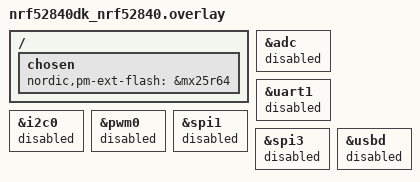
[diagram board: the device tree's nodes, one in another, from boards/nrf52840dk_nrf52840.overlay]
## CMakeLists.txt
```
#
# Copyright (c) 2021 Nordic Semiconductor ASA
#
# SPDX-License-Identifier: LicenseRef-Nordic-5-Clause
#

cmake_minimum_required(VERSION 3.20.0)

find_package(Zephyr REQUIRED HINTS $ENV{ZEPHYR_BASE})
project(matter-lock)

# Enable GNU STD support.
include(${ZEPHYR_CONNECTEDHOMEIP_MODULE_DIR}/config/nrfconnect/app/enable-gnu-std.cmake)

# NORDIC SDK APP START

# Include all source files that are located in the Matter common directory.
include(${ZEPHYR_NRF_MODULE_DIR}/samples/matter/common/cmake/source_common.cmake)

# Include Data Model utils
include(${ZEPHYR_NRF_MODULE_DIR}/samples/matter/common/cmake/data_model.cmake)

include(${ZEPHYR_NRF_MODULE_DIR}/samples/matter/common/cmake/zap_helpers.cmake)
ncs_get_zap_parent_dir(ZAP_PARENT_DIR)

target_include_directories(app PRIVATE
  src
  ${ZAP_PARENT_DIR}
)

SET(access_srcs
  src/access/access_data_types.cpp
  src/access/access_manager_credentials.cpp
  src/access/access_manager_users.cpp
  src/access/access_manager.cpp
  src/access/access_storage.cpp
)

if(CONFIG_LOCK_SCHEDULES)
  LIST(APPEND access_srcs src/access/access_manager_schedules.cpp)
endif()

target_sources(app PRIVATE
  src/app_task.cpp
  src/bolt_lock_manager.cpp
  src/main.cpp
  src/zcl_callbacks.cpp
  ${access_srcs}
)

if(CONFIG_THREAD_WIFI_SWITCHING)
  target_sources(app PRIVATE
    src/thread_wifi_switch.cpp
  )
endif()

# Do not treat warnings as errors while the variable may be uninitialized for this sample data model.
# In the door-lock-server implementation, there is a warning that the C++ "optional"
# variable may be uninitialized, but actually, it is wrongly interpreted by the Zephyr toolchain.
target_compile_options(matter-data-model PRIVATE -Wno-error=maybe-uninitialized)

ncs_configure_data_model()

# NORDIC SDK APP END
```

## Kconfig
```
#
# Copyright (c) 2021 Nordic Semiconductor
#
# SPDX-License-Identifier: LicenseRef-Nordic-5-Clause
#

mainmenu "Matter Lock sample application"

config LOCK_MAX_NUM_USERS
	int "Maximum number of users supported by the lock"
	default 10

config LOCK_MAX_NUM_CREDENTIALS_PER_USER
	int "Maximum total number of credentials per one user supported by the lock"
	default 4

config LOCK_MAX_NUM_CREDENTIALS_PER_TYPE
	int "Maximum number of credentials of given type supported by the lock"
	default 15

config LOCK_MAX_CREDENTIAL_LENGTH
	int "Maximum length of the single credential supported by the lock"
	default 10

config LOCK_PASS_CREDENTIALS_TO_SET_LOCK_STATE
	bool "Pass used credentials when setting the lock state"
	help
	  This option should stay disabled until TC-DRLK-2.3 is fixed.
	  Related issue: https://github.com/project-chip/connectedhomeip/issues/38222

config LOCK_SCHEDULES
	bool "Support for WeekDay, YearDay and Holiday schedules in lock"
	help
	  This option adds support for an optional Timed Schedule Access Lock feature.
	  You can use Week Day, Year Day and Holiday schedules to restrict access for a
	  specific user for a defined time window. For example, use it to
	  give the user access only for three days in week.

if LOCK_SCHEDULES

config LOCK_MAX_WEEKDAY_SCHEDULES_PER_USER
	int "Maximum number of WeekDay schedules per one user supported by the lock"
	default 5

config LOCK_MAX_YEARDAY_SCHEDULES_PER_USER
	int "Maximum number of YearDay schedules per one user supported by the lock"
	default 5

config LOCK_MAX_HOLIDAY_SCHEDULES
	int "Maximum number of Holiday schedules supported by the lock"
	default 5

endif

config LOCK_ENABLE_DEBUG
	bool "Debug features to print users and credentials"
	depends on SHELL
	help
	  Debug features allows to checking and printing current users, their state, and
	  associated credentials. Use these with shell commands combinations to read saved credentials
	  or users, and manage them (add, clear, read).

if LOCK_ENABLE_DEBUG

config LOCK_PRINT_STORAGE_STATUS
	bool "Print storage status after each store call"
	help
	  Debug feature to print the debug-level log that contains information of the entry being stored
	  to persistent storage and how many bytes are left to store the new entry. It can be used to verify
	  whether credential, schedule or user entries are written properly to persistent storage.
	  This option should be disabled in production firmware
	  version.

# This should be deterined based on the maximum possible command length that depends on the LOCK_MAX_CREDENTIAL_LENGTH
config SHELL_CMD_BUFF_SIZE
	default 300

endif

config STATE_LEDS
	bool "Use LEDs to indicate the device state"
	default y
	help
	  Use LEDs to render the current state of the device such as the progress of commissioning of
	  the device into a network or the factory reset initiation. Note that setting this option to
	  'n' does not disable the LED indicating the state of the simulated bolt.

config THREAD_WIFI_SWITCHING
	bool "Switching between Thread and Wi-Fi"
	depends on SOC_SERIES_NRF53X
	depends on NET_L2_OPENTHREAD
	depends on CHIP_WIFI
	depends on !CHIP_FACTORY_RESET_ERASE_SETTINGS
	select EXPERIMENTAL
	help
	  Build the application with both Thread and Wi-Fi support and initialize
	  either transport based on the current configuration. A user can switch
	  between Thread and Wi-Fi by pressing and holding Button 3 for more than
	  10 seconds. During the switching, the device is automatically factory
	  reset and rebooted.

if THREAD_WIFI_SWITCHING

config THREAD_WIFI_SWITCHING_SHELL
	bool "Shell command for switching between Thread and Wi-Fi"
	default y if SHELL
	help
	  Add "switch_transport" shell command that initiates switching between
	  Thread and Wi-Fi transport for Matter protocol stack.

endif # THREAD_WIFI_SWITCHING

# Sample configuration used for Thread networking
if OPENTHREAD

choice OPENTHREAD_NORDIC_LIBRARY_CONFIGURATION
	default OPENTHREAD_NORDIC_LIBRARY_MTD
endchoice

choice OPENTHREAD_DEVICE_TYPE
	default OPENTHREAD_MTD
endchoice

config CHIP_ENABLE_ICD_SUPPORT
	default y

# Reduce Thread TX output power to 0 dBm for SED device
config OPENTHREAD_DEFAULT_TX_POWER
	default 0

endif # OPENTHREAD

if BOARD_NRF7002DK_NRF5340_CPUAPP || SHIELD_NRF7002EK || SHIELD_NRF7002EB2

config CHIP_WIFI
	default y
	select DEPRECATED if SOC_SERIES_NRF53X

config NRF_WIFI_LOW_POWER
	default y

endif # BOARD_NRF7002DK_NRF5340_CPUAPP || SHIELD_NRF7002EK || SHIELD_NRF7002EB2

config NCS_SAMPLE_MATTER_PERSISTENT_STORAGE
	default y

# PSA SSF Crypto Client is not ready for the secure storage backend
if !PSA_SSF_CRYPTO_CLIENT

config NCS_SAMPLE_MATTER_SECURE_STORAGE_BACKEND
	default y if !CHIP_WIFI

config NCS_SAMPLE_MATTER_SETTINGS_STORAGE_BACKEND
	default n if !CHIP_WIFI

endif

# Increase the storage capacity if the schedules are enabled with secure storage
# This also implies increasing of the OT and Matter stacks because some operations
# performed during commissioning seem to allocate stack buffers based on the
# maximum possible secure asset size.
if LOCK_SCHEDULES && NCS_SAMPLE_MATTER_SECURE_STORAGE_BACKEND

config NCS_SAMPLE_MATTER_SECURE_STORAGE_MAX_ENTRY_NUMBER
	default 128

config TRUSTED_STORAGE_BACKEND_AEAD_MAX_DATA_SIZE
	default 3072

config OPENTHREAD_THREAD_STACK_SIZE
	default 7168

config CHIP_TASK_STACK_SIZE
	default 10240

config MAIN_STACK_SIZE
	default 7168

endif

source "$(ZEPHYR_CONNECTEDHOMEIP_MODULE_DIR)/config/nrfconnect/chip-module/Kconfig.features"
source "$(ZEPHYR_CONNECTEDHOMEIP_MODULE_DIR)/config/nrfconnect/chip-module/Kconfig.defaults"
source "$(ZEPHYR_NRF_MODULE_DIR)/samples/matter/common/src/Kconfig"
source "Kconfig.zephyr"
```

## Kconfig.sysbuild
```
#
# Copyright (c) 2023 Nordic Semiconductor ASA
#
# SPDX-License-Identifier: LicenseRef-Nordic-5-Clause
#

# This config has to be enabled manually for variants with shields, because sysbuild does not support it.
config WIFI_NRF70
	default y if BOARD_NRF7002DK

#### Radio core selection
config NRF_DEFAULT_IPC_RADIO
	default y

# Enable IEEE802.15.4 serialization to network core
# This config automatically pulls in the `overlay-802154.conf` in the ipc_radio image
config NETCORE_IPC_RADIO_IEEE802154
	default y if SOC_SERIES_NRF53X && !WIFI_NRF70

# Enable Bluetooth serialization to network core
# This config automatically pulls in the `overlay-bt_hci_ipc.conf` in the ipc_radio image
config NETCORE_IPC_RADIO_BT_HCI_IPC
	default y if SOC_SERIES_NRF53X

#### Bootloader
choice BOOTLOADER
	default BOOTLOADER_MCUBOOT if !BOARD_NRF21540DK
endchoice

if BOOTLOADER_MCUBOOT

#### DFU multi-image support
config DFU_MULTI_IMAGE_PACKAGE_BUILD
	default y

config DFU_MULTI_IMAGE_PACKAGE_APP
	default y

config PM_EXTERNAL_FLASH_MCUBOOT_SECONDARY
	default y

#### DFU network core configuration
if SOC_SERIES_NRF53X

choice MCUBOOT_MODE
	default MCUBOOT_MODE_OVERWRITE_ONLY
endchoice

choice BOOT_SIGNATURE_TYPE
	default BOOT_SIGNATURE_TYPE_RSA
endchoice

config SECURE_BOOT_NETCORE
	default y

config NETCORE_APP_UPDATE
	default y

config DFU_MULTI_IMAGE_PACKAGE_NET
	default y

endif # SOC_SERIES_NRF53X

if BOARD_NRF54L15DK || BOARD_NRF54LM20DK || BOARD_XIAO_NRF54LM20A

# Disable checking the external drivers for nRF54L15 and nRF54LM20 DKs.
config PM_OVERRIDE_EXTERNAL_DRIVER_CHECK
	default y

endif # BOARD_NRF54L15DK || BOARD_NRF54LM20DK || BOARD_XIAO_NRF54LM20A

endif # BOOTLOADER_MCUBOOT

# Store the Wi-Fi firmware patch on external flash by default for nRF5340 with nRF7002
if WIFI_NRF70 && SOC_NRF5340_CPUAPP

choice WIFI_PATCHES_EXT_FLASH_SUPPORT
	default WIFI_PATCHES_EXT_FLASH_STORE

endchoice

config DFU_MULTI_IMAGE_PACKAGE_WIFI_FW_PATCH
	default y

endif # WIFI_NRF70

#### Enable generating factory data
config MATTER_FACTORY_DATA_GENERATE
	default y if !BOARD_NRF21540DK && !BOARD_XIAO_NRF54LM20A

source "share/sysbuild/Kconfig"
```

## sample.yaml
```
sample:
  description: Matter Lock example
  name: Matter Lock
common:
  tags:
    - sysbuild
    - ci_samples_matter
tests:
  sample.matter.lock.debug:
    sysbuild: true
    build_only: true
    integration_platforms:
      - nrf52840dk/nrf52840
      - nrf5340dk/nrf5340/cpuapp
      - nrf7002dk/nrf5340/cpuapp
      - nrf7002dk/nrf5340/cpuapp/nrf7001
      - nrf54l15dk/nrf54l15/cpuapp
      - nrf54l15dk/nrf54l15/cpuapp/ns
      - nrf54lm20dk/nrf54lm20a/cpuapp
    platform_allow:
      - nrf52840dk/nrf52840
      - nrf5340dk/nrf5340/cpuapp
      - nrf7002dk/nrf5340/cpuapp
      - nrf7002dk/nrf5340/cpuapp/nrf7001
      - nrf54l15dk/nrf54l15/cpuapp
      - nrf54l15dk/nrf54l15/cpuapp/ns
      - nrf54lm20dk/nrf54lm20a/cpuapp
  sample.matter.lock.nrf7002eb2.debug:
    sysbuild: true
    build_only: true
    extra_args:
      - lock_SHIELD=nrf7002eb2
      - SB_CONFIG_WIFI_NRF70=y
    integration_platforms:
      - nrf54lm20dk/nrf54lm20a/cpuapp
    platform_allow:
      - nrf54lm20dk/nrf54lm20a/cpuapp
  sample.matter.lock.release:
    sysbuild: true
    build_only: true
    extra_args:
      - FILE_SUFFIX=release
    integration_platforms:
      - nrf52840dk/nrf52840
      - nrf5340dk/nrf5340/cpuapp
      - nrf7002dk/nrf5340/cpuapp
      - nrf7002dk/nrf5340/cpuapp/nrf7001
      - nrf54l15dk/nrf54l15/cpuapp
      - nrf54lm20dk/nrf54lm20a/cpuapp
    platform_allow:
      - nrf52840dk/nrf52840
      - nrf5340dk/nrf5340/cpuapp
      - nrf7002dk/nrf5340/cpuapp
      - nrf7002dk/nrf5340/cpuapp/nrf7001
      - nrf54l15dk/nrf54l15/cpuapp
      - nrf54lm20dk/nrf54lm20a/cpuapp
  sample.matter.lock.nrf7002eb2.release:
    sysbuild: true
    build_only: true
    extra_args:
      - FILE_SUFFIX=release
      - SB_CONFIG_BOOTLOADER_MCUBOOT=y
      - SB_CONFIG_PARTITION_MANAGER=y
      - lock_SHIELD=nrf7002eb2
      - SB_CONFIG_WIFI_NRF70=y
    integration_platforms:
      - nrf54lm20dk/nrf54lm20a/cpuapp
    platform_allow:
      - nrf54lm20dk/nrf54lm20a/cpuapp
  sample.matter.lock.smp_dfu:
    sysbuild: true
    build_only: true
    extra_args:
      - CONFIG_CHIP_DFU_OVER_BT_SMP=y
    integration_platforms:
      - nrf52840dk/nrf52840
      - nrf5340dk/nrf5340/cpuapp
      - nrf7002dk/nrf5340/cpuapp
      - nrf7002dk/nrf5340/cpuapp/nrf7001
      - nrf54l15dk/nrf54l15/cpuapp
      - nrf54lm20dk/nrf54lm20a/cpuapp
    platform_allow:
      - nrf52840dk/nrf52840
      - nrf5340dk/nrf5340/cpuapp
      - nrf7002dk/nrf5340/cpuapp
      - nrf7002dk/nrf5340/cpuapp/nrf7001
      - nrf54l15dk/nrf54l15/cpuapp
      - nrf54lm20dk/nrf54lm20a/cpuapp
  sample.matter.lock.nrf7002eb2.smp_dfu:
    sysbuild: true
    build_only: true
    extra_args:
      - CONFIG_CHIP_DFU_OVER_BT_SMP=y
      - lock_SHIELD=nrf7002eb2
      - SB_CONFIG_WIFI_NRF70=y
    integration_platforms:
      - nrf54lm20dk/nrf54lm20a/cpuapp
    platform_allow:
      - nrf54lm20dk/nrf54lm20a/cpuapp
  sample.matter.lock.no_dfu.no_fd:
    sysbuild: true
    build_only: true
    extra_args:
      - SB_CONFIG_MATTER_OTA=n
    integration_platforms:
      - nrf21540dk/nrf52840
    platform_allow: nrf21540dk/nrf52840
  sample.matter.lock.thread_wifi_switched.smp_dfu:
    sysbuild: true
    build_only: true
    extra_args:
      - lock_SHIELD=nrf7002ek
      - FILE_SUFFIX=thread_wifi_switched
      - SB_CONFIG_WIFI_PATCHES_EXT_FLASH_STORE=y
      - SB_CONFIG_MCUBOOT_UPDATEABLE_IMAGES=3
      - CONFIG_CHIP_DFU_OVER_BT_SMP=y
      - SB_CONFIG_WIFI_NRF70=y
      - SB_CONFIG_DFU_MULTI_IMAGE_PACKAGE_WIFI_FW_PATCH=y
    integration_platforms:
      - nrf5340dk/nrf5340/cpuapp
    platform_allow: nrf5340dk/nrf5340/cpuapp
  sample.matter.lock.nus:
    sysbuild: true
    build_only: true
    extra_args:
      - CONFIG_CHIP_NUS=y
      - CONFIG_BT_APP_PASSKEY=y
      - CONFIG_CHIP_NUS_FIXED_PASSKEY=112233
    integration_platforms:
      - nrf52840dk/nrf52840
      - nrf5340dk/nrf5340/cpuapp
    platform_allow:
      - nrf52840dk/nrf52840
      - nrf5340dk/nrf5340/cpuapp
      - nrf54l15dk/nrf54l15/cpuapp
  sample.matter.lock.schedules:
    sysbuild: true
    build_only: true
    extra_args:
      - lock_SNIPPET=schedules
    integration_platforms:
      - nrf5340dk/nrf5340/cpuapp
    platform_allow:
      - nrf5340dk/nrf5340/cpuapp
  sample.matter.lock.release.power_consumption:
    sysbuild: true
    build_only: true
    extra_args:
      - FILE_SUFFIX=release
      - CONFIG_NCS_SAMPLE_MATTER_LEDS=n
      - CONFIG_NCS_SAMPLE_MATTER_WATCHDOG=n
      - CONFIG_CHIP_ENABLE_PAIRING_AUTOSTART=y
    integration_platforms:
      - nrf52840dk/nrf52840
      - nrf5340dk/nrf5340/cpuapp
      - nrf54l15dk/nrf54l15/cpuapp
      - nrf54lm20dk/nrf54lm20a/cpuapp
    platform_allow:
      - nrf52840dk/nrf52840
      - nrf5340dk/nrf5340/cpuapp
      - nrf54l15dk/nrf54l15/cpuapp
      - nrf54lm20dk/nrf54lm20a/cpuapp
```

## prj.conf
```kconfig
#
# Copyright (c) 2022 Nordic Semiconductor ASA
#
# SPDX-License-Identifier: LicenseRef-Nordic-5-Clause
#

# This sample uses Kconfig.defaults to set options common for all
# samples. This file should contain only options specific for this sample
# or overrides of default values.

# Enable CHIP
CONFIG_CHIP=y
CONFIG_CHIP_PROJECT_CONFIG="src/chip_project_config.h"
CONFIG_CHIP_DEVICE_PRODUCT_NAME="Matter Door Lock"

# Configure ZAP file name
CONFIG_NCS_SAMPLE_MATTER_ZAP_FILE_PATH="${APPLICATION_CONFIG_DIR}/src/default_zap/lock.zap"

# 32774 == 0x8006 (example lock-app)
CONFIG_CHIP_DEVICE_PRODUCT_ID=32774
CONFIG_STD_CPP17=y

# Enable Matter extended announcement and increase duration to 1 hour.
CONFIG_CHIP_BLE_EXT_ADVERTISING=y
CONFIG_CHIP_BLE_ADVERTISING_DURATION=60

# Add support for LEDs and buttons on Nordic development kits
CONFIG_DK_LIBRARY=y

# Bluetooth Low Energy configuration
CONFIG_BT_DEVICE_NAME="MatterLock"

# Suspend devices when the CPU goes into sleep
CONFIG_PM_DEVICE=y

# Other settings
CONFIG_THREAD_NAME=y
CONFIG_MPU_STACK_GUARD=y
CONFIG_RESET_ON_FATAL_ERROR=n
CONFIG_CHIP_LIB_SHELL=y
CONFIG_NCS_SAMPLE_MATTER_TEST_SHELL=y

# Reduce application size
CONFIG_USE_SEGGER_RTT=n
CONFIG_MATTER_LOG_LEVEL_INF=y
CONFIG_CHIP_APP_LOG_LEVEL=3

# Enable Factory Data feature
CONFIG_CHIP_FACTORY_DATA=y
CONFIG_CHIP_FACTORY_DATA_BUILD=y
```

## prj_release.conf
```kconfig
#
# Copyright (c) 2022 Nordic Semiconductor ASA
#
# SPDX-License-Identifier: LicenseRef-Nordic-5-Clause
#

# This sample uses Kconfig.defaults to set options common for all
# samples. This file should contain only options specific for this sample
# or overrides of default values.

# Enable CHIP
CONFIG_CHIP=y
CONFIG_CHIP_PROJECT_CONFIG="src/chip_project_config.h"
CONFIG_CHIP_DEVICE_PRODUCT_NAME="Matter Door Lock"

# Configure ZAP file name
CONFIG_NCS_SAMPLE_MATTER_ZAP_FILE_PATH="${APPLICATION_CONFIG_DIR}/src/default_zap/lock.zap"

# 32774 == 0x8006 (example lock-app)
CONFIG_CHIP_DEVICE_PRODUCT_ID=32774
CONFIG_STD_CPP17=y

# Enable Matter extended announcement and increase duration to 1 hour.
CONFIG_CHIP_BLE_EXT_ADVERTISING=y
CONFIG_CHIP_BLE_ADVERTISING_DURATION=60

# Add support for LEDs and buttons on Nordic development kits
CONFIG_DK_LIBRARY=y

# Bluetooth Low Energy configuration
CONFIG_BT_DEVICE_NAME="MatterLock"

# Suspend devices when the CPU goes into sleep
CONFIG_PM_DEVICE=y

# Enable system reset on fatal error
CONFIG_RESET_ON_FATAL_ERROR=y

# Try to disable unused RAM blocks to reduce power consumption
CONFIG_RAM_POWER_DOWN_LIBRARY=y

# Disable all debug features
CONFIG_USE_SEGGER_RTT=n
CONFIG_SHELL=n
CONFIG_OPENTHREAD_SHELL=n
CONFIG_CONSOLE=n
CONFIG_UART_CONSOLE=n
CONFIG_SERIAL=n
CONFIG_LOG=n
CONFIG_LOG_MODE_MINIMAL=n
CONFIG_ASSERT_VERBOSE=n
CONFIG_ASSERT_NO_FILE_INFO=y
CONFIG_PRINTK=n
CONFIG_PRINTK_SYNC=n
CONFIG_THREAD_NAME=n
CONFIG_BOOT_BANNER=n

# Enable Factory Data feature
CONFIG_CHIP_FACTORY_DATA=y
CONFIG_CHIP_FACTORY_DATA_BUILD=y

# Enable Watchdog
CONFIG_NCS_SAMPLE_MATTER_WATCHDOG=y

# Enable LTO to decrease the flash usage.
CONFIG_LTO=y
CONFIG_ISR_TABLES_LOCAL_DECLARATION=y
```

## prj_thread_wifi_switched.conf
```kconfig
#
# Copyright (c) 2022 Nordic Semiconductor ASA
#
# SPDX-License-Identifier: LicenseRef-Nordic-5-Clause
#

# This sample uses Kconfig.defaults to set options common for all
# samples. This file should contain only options specific for this sample
# or overrides of default values.

# Enable CHIP
CONFIG_CHIP=y
CONFIG_CHIP_PROJECT_CONFIG="src/chip_project_config.h"
CONFIG_CHIP_DEVICE_PRODUCT_NAME="Matter Door Lock"

# Configure ZAP file name
CONFIG_NCS_SAMPLE_MATTER_ZAP_FILE_PATH="${APPLICATION_CONFIG_DIR}/src/default_zap/lock.zap"

# 32774 == 0x8006 (example lock-app)
CONFIG_CHIP_DEVICE_PRODUCT_ID=32774
CONFIG_STD_CPP17=y

# Enable Matter extended announcement and increase duration to 1 hour.
CONFIG_CHIP_BLE_EXT_ADVERTISING=y
CONFIG_CHIP_BLE_ADVERTISING_DURATION=60

# Add support for LEDs and buttons on Nordic development kits
CONFIG_DK_LIBRARY=y

# Bluetooth Low Energy configuration
CONFIG_BT_DEVICE_NAME="MatterLock"

# Other settings
CONFIG_MPU_STACK_GUARD=y
CONFIG_RESET_ON_FATAL_ERROR=n

# Enable switching between Thread and Wi-Fi variants
CONFIG_THREAD_WIFI_SWITCHING=y
CONFIG_THREAD_WIFI_SWITCHING_SHELL=y
CONFIG_CHIP_WIFI=y
CONFIG_NET_L2_OPENTHREAD=y
CONFIG_CHIP_FACTORY_RESET_ERASE_SETTINGS=n # Do not restore initial transport on factory reset

# Reduce application size
CONFIG_USE_SEGGER_RTT=n
CONFIG_WIFI_NM_WPA_SUPPLICANT_ADVANCED_FEATURES=n
CONFIG_CHIP_NFC_ONBOARDING_PAYLOAD=n
CONFIG_MATTER_LOG_LEVEL_INF=y
CONFIG_CHIP_APP_LOG_LEVEL=3
CONFIG_THREAD_NAME=n
CONFIG_BOOT_BANNER=n

# Enable Factory Data feature
CONFIG_CHIP_FACTORY_DATA=y
CONFIG_CHIP_FACTORY_DATA_BUILD=y

# Enable LTO to decrease the flash usage.
CONFIG_LTO=y
CONFIG_ISR_TABLES_LOCAL_DECLARATION=y

# Enforce the use of mbedTLS crypto backend instead of PSA Crypto by
# building OpenThread from sources. Wi-Fi stack does not support PSA Crypto yet.
CONFIG_OPENTHREAD_SOURCES=y
```

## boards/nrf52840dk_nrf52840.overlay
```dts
/*
 * Copyright (c) 2021 Nordic Semiconductor ASA
 *
 * SPDX-License-Identifier: LicenseRef-Nordic-5-Clause
 */

/ {
	chosen {
		nordic,pm-ext-flash = &mx25r64;
	};
};

/* Disable unused peripherals to reduce power consumption */
&adc {
	status = "disabled";
};
&uart1 {
	status = "disabled";
};
&i2c0 {
	status = "disabled";
};
&pwm0 {
	status = "disabled";
};
&spi1 {
	status = "disabled";
};
&spi3 {
	status = "disabled";
};
&usbd {
	status = "disabled";
};
```

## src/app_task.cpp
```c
/*
 * Copyright (c) 2021 Nordic Semiconductor ASA
 *
 * SPDX-License-Identifier: LicenseRef-Nordic-5-Clause
 */

#include "app_task.h"
#include "bolt_lock_manager.h"
#include "clusters/identify.h"

#ifdef CONFIG_THREAD_WIFI_SWITCHING
#include "thread_wifi_switch.h"
#endif

#include "app/matter_init.h"
#include "app/task_executor.h"

#ifdef CONFIG_CHIP_NUS
#include "bt_nus/bt_nus_service.h"
#endif

#include <app-common/zap-generated/attributes/Accessors.h>
#include <app/clusters/door-lock-server/door-lock-server.h>
#include <platform/CHIPDeviceLayer.h>
#include <setup_payload/OnboardingCodesUtil.h>

#include <zephyr/logging/log.h>

LOG_MODULE_DECLARE(app, CONFIG_CHIP_APP_LOG_LEVEL);

using namespace ::chip;
using namespace ::chip::app;
using namespace ::chip::DeviceLayer;

namespace
{
constexpr EndpointId kLockEndpointId = 1;

#ifdef CONFIG_CHIP_NUS
constexpr uint16_t kAdvertisingIntervalMin = 400;
constexpr uint16_t kAdvertisingIntervalMax = 500;
constexpr uint8_t kLockNUSPriority = 2;
#endif

#ifdef CONFIG_THREAD_WIFI_SWITCHING
k_timer sSwitchTransportTimer;
constexpr uint32_t kSwitchTransportTimeout = 10000;
#endif

#define APPLICATION_BUTTON_MASK DK_BTN2_MSK
#define SWITCHING_BUTTON_MASK DK_BTN3_MSK

#ifndef CONFIG_CHIP_FACTORY_RESET_ERASE_SETTINGS
void AppFactoryResetHandler(const ChipDeviceEvent *event, intptr_t /* unused */)
{
	switch (event->Type) {
	case DeviceEventType::kFactoryReset:
		BoltLockMgr().FactoryReset();
		break;
	default:
		break;
	}
}
#endif

Nrf::Matter::IdentifyCluster sIdentifyCluster(kLockEndpointId, false, []() {
	Nrf::PostTask([] { Nrf::GetBoard().GetLED(Nrf::DeviceLeds::LED2).Set(BoltLockMgr().IsLocked()); });
});
} /* namespace */

void AppTask::ButtonEventHandler(Nrf::ButtonState state, Nrf::ButtonMask hasChanged)
{
	if ((APPLICATION_BUTTON_MASK & hasChanged) & state) {
		Nrf::PostTask([] { LockActionEventHandler(); });
	}

#ifdef CONFIG_THREAD_WIFI_SWITCHING
	if (SWITCHING_BUTTON_MASK & hasChanged) {
		SwitchButtonAction action =
			(SWITCHING_BUTTON_MASK & state) ? SwitchButtonAction::Pressed : SwitchButtonAction::Released;
		Nrf::PostTask([action] { SwitchTransportTriggerHandler(action); });
	}
#endif
}

void AppTask::LockActionEventHandler()
{
	if (BoltLockMgr().IsLocked()) {
		BoltLockMgr().Unlock(BoltLockManager::OperationSource::kButton);
	} else {
		BoltLockMgr().Lock(BoltLockManager::OperationSource::kButton);
	}
}

#ifdef CONFIG_THREAD_WIFI_SWITCHING
void AppTask::SwitchTransportEventHandler()
{
	LOG_INF("Switching to %s", ThreadWifiSwitch::IsThreadActive() ? "Wi-Fi" : "Thread");

	ThreadWifiSwitch::SwitchTransport();
}

void AppTask::SwitchTransportTimerTimeoutCallback(k_timer *timer)
{
	Nrf::PostTask([] { SwitchTransportEventHandler(); });
}

void AppTask::SwitchTransportTriggerHandler(const SwitchButtonAction &action)
{
	if (action == SwitchButtonAction::Pressed) {
		LOG_INF("Keep button pressed for %u ms to switch to %s", kSwitchTransportTimeout,
			ThreadWifiSwitch::IsThreadActive() ? "Wi-Fi" : "Thread");
		k_timer_start(&sSwitchTransportTimer, K_MSEC(kSwitchTransportTimeout), K_NO_WAIT);
	} else {
		LOG_INF("Switching to %s cancelled", ThreadWifiSwitch::IsThreadActive() ? "Wi-Fi" : "Thread");
		k_timer_stop(&sSwitchTransportTimer);
	}
}
#endif

void AppTask::LockStateChanged(const BoltLockManager::StateData &stateData)
{
	switch (stateData.mState) {
	case BoltLockManager::State::kLockingInitiated:
		LOG_INF("Lock action initiated");
		Nrf::GetBoard().GetLED(Nrf::DeviceLeds::LED2).Blink(50, 50);
#ifdef CONFIG_CHIP_NUS
		Nrf::GetNUSService().SendData("locking", sizeof("locking"));
#endif
		break;
	case BoltLockManager::State::kLockingCompleted:
		LOG_INF("Lock action completed");
		Nrf::GetBoard().GetLED(Nrf::DeviceLeds::LED2).Set(true);
#ifdef CONFIG_CHIP_NUS
		Nrf::GetNUSService().SendData("locked", sizeof("locked"));
#endif
		break;
	case BoltLockManager::State::kUnlockingInitiated:
		LOG_INF("Unlock action initiated");
		Nrf::GetBoard().GetLED(Nrf::DeviceLeds::LED2).Blink(50, 50);
#ifdef CONFIG_CHIP_NUS
		Nrf::GetNUSService().SendData("unlocking", sizeof("unlocking"));
#endif
		break;
	case BoltLockManager::State::kUnlockingCompleted:
		LOG_INF("Unlock action completed");
#ifdef CONFIG_CHIP_NUS
		Nrf::GetNUSService().SendData("unlocked", sizeof("unlocked"));
#endif
		Nrf::GetBoard().GetLED(Nrf::DeviceLeds::LED2).Set(false);
		break;
	}

	/* Handle changing attribute state in the application */
	Instance().UpdateClusterState(stateData);
}

void AppTask::UpdateClusterState(const BoltLockManager::StateData &stateData)
{
	BoltLockManager::StateData *stateDataCopy = Platform::New<BoltLockManager::StateData>(stateData);

	if (stateDataCopy == nullptr) {
		LOG_ERR("Failed to allocate memory for BoltLockManager::StateData");
		return;
	}

	CHIP_ERROR err = SystemLayer().ScheduleLambda([stateDataCopy]() {
		UpdateClusterStateHandler(*stateDataCopy);
		Platform::Delete(stateDataCopy);
	});

	if (err != CHIP_NO_ERROR) {
		LOG_ERR("Failed to schedule lambda: %" CHIP_ERROR_FORMAT, err.Format());
		Platform::Delete(stateDataCopy);
	}
}

void AppTask::UpdateClusterStateHandler(const BoltLockManager::StateData &stateData)
{
	using namespace chip::app::Clusters::DoorLock::Attributes;

	DlLockState newLockState;

	switch (stateData.mState) {
	case BoltLockManager::State::kLockingCompleted:
		newLockState = DlLockState::kLocked;
		break;
	case BoltLockManager::State::kUnlockingCompleted:
		newLockState = DlLockState::kUnlocked;
		break;
	default:
		newLockState = DlLockState::kNotFullyLocked;
		break;
	}

	Nullable<DlLockState> currentLockState;
	LockState::Get(kLockEndpointId, currentLockState);

	if (currentLockState.IsNull()) {
		/* Initialize lock state with start value, but not invoke lock/unlock. */
		LockState::Set(kLockEndpointId, newLockState);
	} else {
		LOG_INF("Updating LockState attribute");

		Nullable<uint16_t> userId;
		Nullable<List<const LockOpCredentials>> credentials;
#ifdef CONFIG_LOCK_PASS_CREDENTIALS_TO_SET_LOCK_STATE
		List<const LockOpCredentials> credentialList;
#endif

		if (!stateData.mValidatePINResult.IsNull()) {
			userId = { stateData.mValidatePINResult.Value().mUserId };

#ifdef CONFIG_LOCK_PASS_CREDENTIALS_TO_SET_LOCK_STATE
			/* `DoorLockServer::SetLockState` exptects list of `LockOpCredentials`,
			   however in case of PIN validation it makes no sense to have more than one
			   credential corresponding to validation result. For simplicity we wrap single
			   credential in list here. */
			credentialList = { &stateData.mValidatePINResult.Value().mCredential, 1 };
			credentials = { credentialList };
#endif
		}

		if (!DoorLockServer::Instance().SetLockState(kLockEndpointId, newLockState, stateData.mSource, userId,
							     credentials, stateData.mFabricIdx, stateData.mNodeId)) {
			LOG_ERR("Failed to update LockState attribute");
		}
	}
}

#ifdef CONFIG_CHIP_NUS
void AppTask::NUSLockCallback(void *context)
{
	LOG_DBG("Received LOCK command from NUS");
	if (BoltLockMgr().GetState().mState == BoltLockManager::State::kLockingCompleted ||
	    BoltLockMgr().GetState().mState == BoltLockManager::State::kLockingInitiated) {
		LOG_INF("Device is already locked");
	} else {
		Nrf::PostTask([] { LockActionEventHandler(); });
	}
}

void AppTask::NUSUnlockCallback(void *context)
{
	LOG_DBG("Received UNLOCK command from NUS");
	if (BoltLockMgr().GetState().mState == BoltLockManager::State::kUnlockingCompleted ||
	    BoltLockMgr().GetState().mState == BoltLockManager::State::kUnlockingInitiated) {
		LOG_INF("Device is already unlocked");
	} else {
		Nrf::PostTask([] { LockActionEventHandler(); });
	}
}
#endif

#ifdef CONFIG_NCS_SAMPLE_MATTER_TEST_EVENT_TRIGGERS
CHIP_ERROR AppTask::DoorLockJammedEventCallback(Nrf::Matter::TestEventTrigger::TriggerValue)
{
	VerifyOrReturnError(DoorLockServer::Instance().SendLockAlarmEvent(kLockEndpointId, AlarmCodeEnum::kLockJammed),
			    CHIP_ERROR_INTERNAL);
	LOG_ERR("Event Trigger: Doorlock jammed.");
	return CHIP_NO_ERROR;
}
#endif

CHIP_ERROR AppTask::Init()
{
	/* Initialize Matter stack */
#ifdef CONFIG_THREAD_WIFI_SWITCHING
	/* In the Thread/Wi-Fi switchable mode, it is the ThreadWifiSwitch module that owns the NetworkCommissioning
	   instances, so offload the initialization module from controlling that by explicitly setting the
	   mNetworkingInstance parameter to nullptr. Otherwise, the initialization module instantiates the
	   NetworkCommissioning object and handles it by default internally. */
	ReturnErrorOnFailure(Nrf::Matter::PrepareServer(Nrf::Matter::InitData{ .mNetworkingInstance = nullptr }));
#else
	ReturnErrorOnFailure(Nrf::Matter::PrepareServer());
#endif

	if (!Nrf::GetBoard().Init(ButtonEventHandler)) {
		LOG_ERR("User interface initialization failed.");
		return CHIP_ERROR_INCORRECT_STATE;
	}

	/* Register Matter event handler that controls the connectivity status LED based on the captured Matter network
	 * state. */
	ReturnErrorOnFailure(Nrf::Matter::RegisterEventHandler(Nrf::Board::DefaultMatterEventHandler, 0));

#ifndef CONFIG_CHIP_FACTORY_RESET_ERASE_SETTINGS
	/* Register factory reset event handler.
	 * With this configuration we have to manually clean up the storage,
	 * as whole settings partition won't be erased.
	 * */
	ReturnErrorOnFailure(Nrf::Matter::RegisterEventHandler(AppFactoryResetHandler, 0));
#endif

#ifdef CONFIG_THREAD_WIFI_SWITCHING
	CHIP_ERROR err = ThreadWifiSwitch::StartCurrentTransport();
	if (err != CHIP_NO_ERROR) {
		LOG_ERR("ThreadWifiSwitch::StartCurrentTransport() failed: %" CHIP_ERROR_FORMAT, err.Format());
		return err;
	}

	k_timer_init(&sSwitchTransportTimer, &AppTask::SwitchTransportTimerTimeoutCallback, nullptr);
#endif

#ifdef CONFIG_CHIP_NUS
	/* Initialize Nordic UART Service for Lock purposes */
	if (!Nrf::GetNUSService().Init(kLockNUSPriority, kAdvertisingIntervalMin, kAdvertisingIntervalMax)) {
		ChipLogError(Zcl, "Cannot initialize NUS service");
	}
	Nrf::GetNUSService().RegisterCommand("Lock", sizeof("Lock"), NUSLockCallback, nullptr);
	Nrf::GetNUSService().RegisterCommand("Unlock", sizeof("Unlock"), NUSUnlockCallback, nullptr);
	if (!Nrf::GetNUSService().StartServer()) {
		LOG_ERR("GetNUSService().StartServer() failed");
	}
#endif

	/* Initialize lock manager */
	BoltLockMgr().Init(LockStateChanged);

	/* Register Door Lock test event trigger */
#ifdef CONFIG_NCS_SAMPLE_MATTER_TEST_EVENT_TRIGGERS
	ReturnErrorOnFailure(Nrf::Matter::TestEventTrigger::Instance().RegisterTestEventTrigger(
		kDoorLockJammedEventTriggerId,
		Nrf::Matter::TestEventTrigger::EventTrigger{ 0, DoorLockJammedEventCallback }));
#endif

	ReturnErrorOnFailure(sIdentifyCluster.Init());

	return Nrf::Matter::StartServer();
}

CHIP_ERROR AppTask::StartApp()
{
	ReturnErrorOnFailure(Init());

	while (true) {
		Nrf::DispatchNextTask();
	}

	return CHIP_NO_ERROR;
}
```

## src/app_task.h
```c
/*
 * Copyright (c) 2021 Nordic Semiconductor ASA
 *
 * SPDX-License-Identifier: LicenseRef-Nordic-5-Clause
 */

#pragma once

#include "board/board.h"
#include "board/led_widget.h"
#include "bolt_lock_manager.h"

struct k_timer;
struct Identify;

#ifdef CONFIG_THREAD_WIFI_SWITCHING
enum class SwitchButtonAction : uint8_t { Pressed, Released };
#endif

#ifdef CONFIG_NCS_SAMPLE_MATTER_TEST_EVENT_TRIGGERS
#include "event_triggers/event_triggers.h"
#endif

class AppTask {
public:
	static AppTask &Instance()
	{
		static AppTask sAppTask;
		return sAppTask;
	};

	CHIP_ERROR StartApp();

	void UpdateClusterState(const BoltLockManager::StateData &stateData);

private:
	CHIP_ERROR Init();

	static void LockActionEventHandler();
	static void ButtonEventHandler(Nrf::ButtonState state, Nrf::ButtonMask hasChanged);
	static void LockStateChanged(const BoltLockManager::StateData &stateData);
	static void UpdateClusterStateHandler(const BoltLockManager::StateData &stateData);

#ifdef CONFIG_THREAD_WIFI_SWITCHING
	static void SwitchTransportEventHandler();
	static void SwitchTransportTimerTimeoutCallback(k_timer *timer);
	static void SwitchTransportTriggerHandler(const SwitchButtonAction &action);
#endif

#ifdef CONFIG_CHIP_NUS
	static void NUSLockCallback(void *context);
	static void NUSUnlockCallback(void *context);
#endif

#ifdef CONFIG_NCS_SAMPLE_MATTER_TEST_EVENT_TRIGGERS
	constexpr static Nrf::Matter::TestEventTrigger::EventTriggerId kDoorLockJammedEventTriggerId =
		0xFFFF'FFFF'3277'4000;
	static CHIP_ERROR DoorLockJammedEventCallback(Nrf::Matter::TestEventTrigger::TriggerValue);
#endif
};
```

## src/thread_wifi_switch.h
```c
/*
 * Copyright (c) 2023 Nordic Semiconductor ASA
 *
 * SPDX-License-Identifier: LicenseRef-Nordic-5-Clause
 */

#include <lib/core/CHIPError.h>

namespace ThreadWifiSwitch
{
/**
 * Returns whether it is Thread and not Wi-Fi that is currently used as a Matter transport.
 */
bool IsThreadActive();

/**
 * Start either Thread or Wi-Fi Matter transport based on the current configuration.
 *
 * Initializes Matter components, such as network commissioning instance or DNS-SD
 * implementation, based on the active Matter transport.
 */
CHIP_ERROR StartCurrentTransport();

/**
 * Initiates switching between Thread and Wi-Fi.
 *
 * The switching involves resetting the device to its factory setting, setting a flag
 * indicating the active transport, and rebooting the device.
 */
void SwitchTransport();
} /* namespace ThreadWifiSwitch */
```

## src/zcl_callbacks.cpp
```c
/*
 * Copyright (c) 2021 Nordic Semiconductor ASA
 *
 * SPDX-License-Identifier: LicenseRef-Nordic-5-Clause
 */

#include "app_task.h"
#include "bolt_lock_manager.h"

#include <app-common/zap-generated/attributes/Accessors.h>
#include <app-common/zap-generated/ids/Clusters.h>
#include <app/ConcreteAttributePath.h>
#include <app/clusters/door-lock-server/door-lock-server.h>
#include <app/data-model/Nullable.h>
#include <lib/core/DataModelTypes.h>
#include <lib/support/CodeUtils.h>

using namespace ::chip;
using namespace ::chip::app::Clusters;
using namespace ::chip::app::Clusters::DoorLock;
using ::chip::app::DataModel::Nullable;

void MatterPostAttributeChangeCallback(const chip::app::ConcreteAttributePath &attributePath, uint8_t type,
				       uint16_t size, uint8_t *value)
{
	VerifyOrReturn(attributePath.mClusterId == DoorLock::Id);

	if (attributePath.mAttributeId == DoorLock::Attributes::RequirePINforRemoteOperation::Id) {
		BoltLockMgr().SetRequirePIN(*value);
	}
}

bool emberAfPluginDoorLockGetUser(EndpointId endpointId, uint16_t userIndex, EmberAfPluginDoorLockUserInfo &user)
{
	return BoltLockMgr().GetUser(userIndex, user);
}

bool emberAfPluginDoorLockSetUser(EndpointId endpointId, uint16_t userIndex, FabricIndex creator, FabricIndex modifier,
				  const CharSpan &userName, uint32_t uniqueId, UserStatusEnum userStatus,
				  UserTypeEnum userType, CredentialRuleEnum credentialRule,
				  const CredentialStruct *credentials, size_t totalCredentials)
{
	return BoltLockMgr().SetUser(userIndex, creator, modifier, userName, uniqueId, userStatus, userType,
				     credentialRule, credentials, totalCredentials);
}

bool emberAfPluginDoorLockGetCredential(EndpointId endpointId, uint16_t credentialIndex,
					CredentialTypeEnum credentialType,
					EmberAfPluginDoorLockCredentialInfo &credential)
{
	return BoltLockMgr().GetCredential(credentialIndex, credentialType, credential);
}

bool emberAfPluginDoorLockSetCredential(EndpointId endpointId, uint16_t credentialIndex, FabricIndex creator,
					FabricIndex modifier, DlCredentialStatus credentialStatus,
					CredentialTypeEnum credentialType, const ByteSpan &secret)
{
	return BoltLockMgr().SetCredential(credentialIndex, creator, modifier, credentialStatus, credentialType,
					   secret);
}

bool emberAfPluginDoorLockOnDoorLockCommand(EndpointId endpointId, const Nullable<chip::FabricIndex> &fabricIdx,
					    const Nullable<chip::NodeId> &nodeId, const Optional<ByteSpan> &pinCode,
					    OperationErrorEnum &err)
{
	Nullable<BoltLockManager::ValidatePINResult> validatePINResult;
	bool success = BoltLockMgr().ValidatePIN(pinCode, err, validatePINResult);

	/* Handle changing attribute state on command reception */
	if (success) {
		BoltLockMgr().Lock(BoltLockManager::OperationSource::kRemote, fabricIdx, nodeId, validatePINResult);
	}

	return success;
}

bool emberAfPluginDoorLockOnDoorUnlockCommand(EndpointId endpointId, const Nullable<chip::FabricIndex> &fabricIdx,
					      const Nullable<chip::NodeId> &nodeId, const Optional<ByteSpan> &pinCode,
					      OperationErrorEnum &err)
{
	Nullable<BoltLockManager::ValidatePINResult> validatePINResult;
	bool success = BoltLockMgr().ValidatePIN(pinCode, err, validatePINResult);

	/* Handle changing attribute state on command reception */
	if (success) {
		BoltLockMgr().Unlock(BoltLockManager::OperationSource::kRemote, fabricIdx, nodeId, validatePINResult);
	}

	return success;
}

void emberAfPluginDoorLockOnAutoRelock(chip::EndpointId endpointId)
{
	BoltLockMgr().Lock(BoltLockManager::OperationSource::kAuto);
}

void emberAfDoorLockClusterInitCallback(EndpointId endpoint)
{
	DoorLockServer::Instance().InitServer(endpoint);

	const auto logOnFailure = [](Protocols::InteractionModel::Status status, const char *attributeName) {
		if (status != Protocols::InteractionModel::Status::Success) {
			ChipLogError(Zcl, "Failed to set DoorLock %s: %x", attributeName, to_underlying(status));
		}
	};

	logOnFailure(DoorLock::Attributes::LockType::Set(endpoint, DlLockType::kDeadBolt), "type");
	logOnFailure(DoorLock::Attributes::NumberOfTotalUsersSupported::Set(endpoint, CONFIG_LOCK_MAX_NUM_USERS),
		     "number of users");
	logOnFailure(DoorLock::Attributes::NumberOfPINUsersSupported::Set(endpoint,
									  CONFIG_LOCK_MAX_NUM_CREDENTIALS_PER_TYPE),
		     "number of PIN users");
	logOnFailure(DoorLock::Attributes::NumberOfRFIDUsersSupported::Set(endpoint, 0), "number of RFID users");
	logOnFailure(DoorLock::Attributes::NumberOfCredentialsSupportedPerUser::Set(
			     endpoint, CONFIG_LOCK_MAX_NUM_CREDENTIALS_PER_USER),
		     "number of credentials per user");
	logOnFailure(DoorLock::Attributes::RequirePINforRemoteOperation::Set(endpoint, BoltLockMgr().GetRequirePIN()),
		     "require PIN code for the remote operation");

#ifdef CONFIG_LOCK_SCHEDULES
	logOnFailure(DoorLock::Attributes::NumberOfWeekDaySchedulesSupportedPerUser::Set(
			     endpoint, CONFIG_LOCK_MAX_WEEKDAY_SCHEDULES_PER_USER),
		     "number of WeekDay schedules per user");
	logOnFailure(DoorLock::Attributes::NumberOfYearDaySchedulesSupportedPerUser::Set(
			     endpoint, CONFIG_LOCK_MAX_YEARDAY_SCHEDULES_PER_USER),
		     "number of YearDay schedules per user");
	logOnFailure(DoorLock::Attributes::NumberOfHolidaySchedulesSupported::Set(endpoint,
										  CONFIG_LOCK_MAX_HOLIDAY_SCHEDULES),
		     "number of holiday schedules");
#endif /* CONFIG_LOCK_SCHEDULES */

	BoltLockManager::StateData state = BoltLockMgr().GetState();
	state.mSource = BoltLockManager::OperationSource::kUnspecified;
	AppTask::Instance().UpdateClusterState(state);
}

#ifdef CONFIG_LOCK_SCHEDULES

DlStatus emberAfPluginDoorLockGetSchedule(chip::EndpointId endpointId, uint8_t weekdayIndex, uint16_t userIndex,
					  EmberAfPluginDoorLockWeekDaySchedule &schedule)
{
	return BoltLockMgr().GetWeekDaySchedule(weekdayIndex, userIndex, schedule);
}

DlStatus emberAfPluginDoorLockGetSchedule(chip::EndpointId endpointId, uint8_t yearDayIndex, uint16_t userIndex,
					  EmberAfPluginDoorLockYearDaySchedule &schedule)
{
	return BoltLockMgr().GetYearDaySchedule(yearDayIndex, userIndex, schedule);
}

DlStatus emberAfPluginDoorLockGetSchedule(chip::EndpointId endpointId, uint8_t holidayIndex,
					  EmberAfPluginDoorLockHolidaySchedule &holidaySchedule)
{
	return BoltLockMgr().GetHolidaySchedule(holidayIndex, holidaySchedule);
}

DlStatus emberAfPluginDoorLockSetSchedule(chip::EndpointId endpointId, uint8_t weekdayIndex, uint16_t userIndex,
					  DlScheduleStatus status, DaysMaskMap daysMask, uint8_t startHour,
					  uint8_t startMinute, uint8_t endHour, uint8_t endMinute)
{
	return BoltLockMgr().SetWeekDaySchedule(weekdayIndex, userIndex, status, daysMask, startHour, startMinute,
						endHour, endMinute);
}

DlStatus emberAfPluginDoorLockSetSchedule(chip::EndpointId endpointId, uint8_t yearDayIndex, uint16_t userIndex,
					  DlScheduleStatus status, uint32_t localStartTime, uint32_t localEndTime)
{
	return BoltLockMgr().SetYearDaySchedule(yearDayIndex, userIndex, status, localStartTime, localEndTime);
}

DlStatus emberAfPluginDoorLockSetSchedule(chip::EndpointId endpointId, uint8_t holidayIndex, DlScheduleStatus status,
					  uint32_t localStartTime, uint32_t localEndTime,
					  OperatingModeEnum operatingMode)
{
	return BoltLockMgr().SetHolidaySchedule(holidayIndex, status, localStartTime, localEndTime, operatingMode);
}

#endif /* CONFIG_LOCK_SCHEDULES */
```
